# AE101F4071542LH_CM55_HE_View register map
Vendor: Alif Semiconductor; Series: E1; File version: 1.0
CPU: CM55 r1p0, selectable endian, MPU, FPU, double-precision FPU, DSP, VTOR, 8 interrupt priority bits, 1 SAU regions
Registers are 32-bit, read-write, reset 0x0 unless marked. A register's access mark holds for its fields unless they carry their own. Offsets are from the block's base; [hi:lo] are bit positions; 'fields as' and 'values as' point back to an identical list.

## AON
Base 0x1A604000
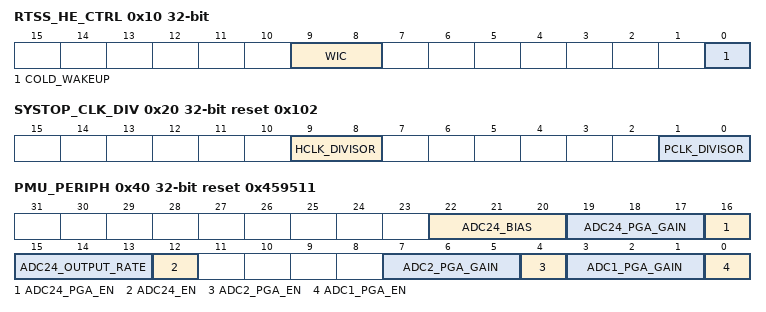
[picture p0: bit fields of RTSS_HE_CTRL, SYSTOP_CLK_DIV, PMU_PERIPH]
0x10 RTSS_HE_CTRL — RTSS-HE Control Register
  [9:8] WIC — Control bits mapped to WICCONTROL[1:0] configuration signal of M55-HE. Bit [9] is mapped to WICCONTROL[1]. Bit [8] is mapped to WICCONTROL[0]. For more information, refer to Arm(R) Cortex(R)-M55 Processor Technical Reference Manual.
  [0] COLD_WAKEUP — Set this bit to wake up RTSS-HE power domain during cold boot or waking-up from stop mode. Clear it once power-on sequence is complete to enable dynamic power transitions of RTSS-HE.
0x14 RTSS_HE_RESET reset 0x1 — RTSS-HE Reset Status Register
  [5:0] RESETSYNDROME wo write-1-clears — Reset status bits set by hardware and cleared by software. Bit 0: Indicates the last reset of RTSS-HE was caused by POR or Secure Enclave initiated reset Bit 1: Indicates the last reset of RTSS-HE was caused by NSRST pin being asserted Bit 2: Reserved Bit 3: Indicates the last reset of RTSS-HE was caused by a host system reset request by Secure Enclave Bit 4: Indicates the last reset of RTSS-HE was caused by a reset request to the power domain Bit 5: Reserved
0x18 RTSS_HE_CLK_FORCE — RTSS-HE Clocks Override Register
  [31:0] CLK_FORCE — RTSS-HE clocks override. Bits [31-28]: Unused Bit [27]: Force NPU-HE TOP clock Bit [26]: Force CPU TOP clock Bit [25]: Force debug TOP clock Bit [24]: Force host TOP clock Bits [23-16]: Quiescence entry delay for all four RTSS-HE TOP clock controllers Bits [15-9]: Unused Bit [8]: Force AON clock Bits [7-0]: Quiescence entry delay for AON clock controller
0x1C RTSS_HE_LPUART_CKEN — LPUART Clock Enable Register
  [0] UART_CKEN — Enable clock for LPUART
    0=Disable clock; 1=Enable clock
0x20 SYSTOP_CLK_DIV reset 0x102 — System Bus Clock Divider Control Register
  [9:8] HCLK_DIVISOR — SYST_HCLK clock divisor
    0=Divide by 1; 1=Divide by 2; 2=Divide by 4; 3=Divide by 4
  [1:0] PCLK_DIVISOR — SYST_PCLK clock divisor
    0=Divide by 1; 1=Divide by 2; 2=Divide by 4; 3=Divide by 4
0x30 MISC_REG1 — HFXO Divider Control Register
  [16:13] CLKDIV — HFXO divisor
    0=Divide by 1; 1=Divide by 2; 2=Divide by 4; 3=Divide by 8; 4=Divide by 16; 5=Divide by 32; 6=Divide by 64; 7=Divide by 128; 8=Divide by 1; 9=Divide by 2; 10=Divide by 4; 11=Divide by 16; 12=Divide by 64; 13=Divide by 128; 14=Divide by 256; 15=Divide by 1024
0x40 PMU_PERIPH reset 0x459511 — ADC Control Register
  [22:20] ADC24_BIAS — ADC24 bias control
  [19:17] ADC24_PGA_GAIN — ADC24 PGA gain value:
    0=Do not use; 1=6 dB; 2=12 dB; 3=18 dB; 4=24 dB; 5=30 dB; 6=36 dB; 7=42 dB
  [16] ADC24_PGA_EN — ADC24 PGA enable
    0=Disabled; 1=Enabled
  [15:13] ADC24_OUTPUT_RATE — ADC24 output rate select: Other values should not be used.
    0=Val_0b000 (1 kS/s); 1=Val_0b001 (2 kS/s); 2=Val_0b010 (4 kS/s); 3=Val_0b011 (8 kS/s); 4=Val_0b100 (16 kS/s)
  [12] ADC24_EN — ADC24 enable
    0=Disabled; 1=Enabled
  [7:5] ADC2_PGA_GAIN — ADC121 PGA gain value select: Other values should not be used.
    0=Val_0b000 (4 dB); 1=Val_0b001 (8 dB); 4=Val_0b100 (12 dB); 5=Val_0b101 (16 dB); 6=Val_0b110 (20 dB)
  [4] ADC2_PGA_EN — ADC121 PGA enable Note: ADC121 must be put into differential mode when PGA is enabled
    0=Disabled; 1=Enabled
  [3:1] ADC1_PGA_GAIN — ADC120 PGA gain value select: Other values should not be used.
    values as ADC2_PGA_GAIN
  [0] ADC1_PGA_EN — ADC120 PGA enable Note: ADC120 must be put into differential mode when PGA is enabled
    0=Disabled; 1=Enabled

## VBAT
Base 0x1A609000
0x00 GPIO_CTRL — GPIO 1.8 V / 3.3 V Power Control Register
  [0] VOLT — Select voltage level for the 1.8-V/3.3-V (flex) I/O pins
    0=I/O pin will be used with a 3.3-V power; 1=I/O pin will be used with a 1.8-V power
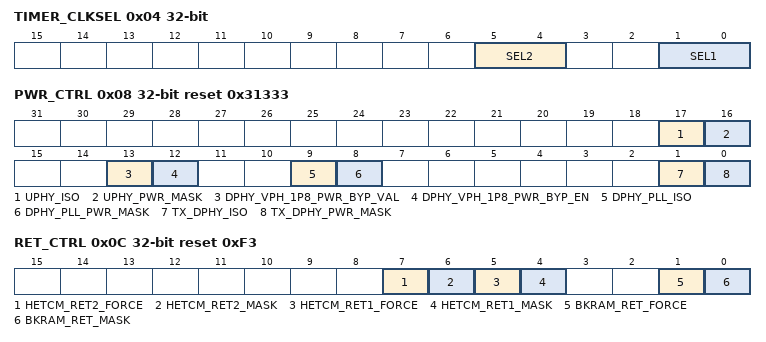
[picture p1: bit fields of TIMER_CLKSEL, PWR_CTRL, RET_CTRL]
0x04 TIMER_CLKSEL — LPTIMER Clock Select Register
  [5:4] SEL2 — LPTIMER1 clock select
    0=S32K_CLK; 1=128K_CLK (128 kHz); 2=External clock from LPTMR1_CLK_IO pin; 3=LPTIMER0 toggle output (LPTMR0_OUT)
  [1:0] SEL1 — LPTIMER0 clock select
    0=S32K_CLK; 1=128K_CLK (128 kHz); 2=External clock from LPTMR0_CLK_IO pin; 3=S32K_CLK
0x08 PWR_CTRL reset 0x31333 — Power Control Register
  [17] UPHY_ISO — Enable isolation for USB PHY
    0=Disable; 1=Enable
  [16] UPHY_PWR_MASK — Mask off the power for USB PHY
    0=Power not masked; 1=Power masked off
  [13] DPHY_VPH_1P8_PWR_BYP_VAL — Power setting for MIPI D-PHY 1.8 V supply. The setting is used only if DPHY_VPH_1P8_PWR_BYP_EN bit is enabled.
    0=Power disabled; 1=Power enabled
  [12] DPHY_VPH_1P8_PWR_BYP_EN — Power mode for MIPI D-PHY 1.8 V supply
    0=Power enabled whenever PD-6 is enabled; 1=Power specified by DPHY_VPH_1P8_PWR_BYP_VAL bit
  [9] DPHY_PLL_ISO — Enable isolation for MIPI PLL
    0=Disable; 1=Enable
  [8] DPHY_PLL_PWR_MASK — Mask off the power for MIPI PLL
    0=Power not masked; 1=Power masked off
  [1] TX_DPHY_ISO — Enable isolation for MIPI TX DPHY
    0=Disable; 1=Enable
  [0] TX_DPHY_PWR_MASK — Mask off the power for MIPI TX DPHY
    0=Power not masked; 1=Power masked off
0x0C RET_CTRL reset 0xF3 — Memory Retention Control Register
  [7] HETCM_RET2_FORCE — Memory retention force for M55-HE TCM RET2
    0=Force enabling the memory retention; 1=No force
  [6] HETCM_RET2_MASK — Memory retention mask for M55-HE TCM RET2
    0=No mask; 1=Disable the memory retention
  [5] HETCM_RET1_FORCE — Memory retention force for M55-HE TCM RET1
    0=Force enabling the memory retention; 1=No force
  [4] HETCM_RET1_MASK — Memory retention mask for M55-HE TCM RET1
    0=No mask; 1=Disable the memory retention
  [1] BKRAM_RET_FORCE — Memory retention force for Utility SRAM
    0=Force enabling the memory retention; 1=No force
  [0] BKRAM_RET_MASK — Memory retention mask for Utility SRAM
    0=No mask; 1=Disable the memory retention
0x10 RTC_CLK_EN — LPRTC Clock Enable Register
  [0] CLK_EN — Enable SYST_PCLK and S32K_CLK for LPRTC. This bit must be set before any programming to LPRTC.
    0=Disable LPRTC clocks; 1=Enable LPRTC clocks
